# RT register map
Vendor: Texas Instruments
Peripheral module from a debugger description file (folder omap36xx).
Registers are 64-bit, read-only, reset values left out (the file's numbers can be read two ways) unless marked. A register's access mark holds for its fields unless they carry their own. Offsets are as the file gives them; lines under a group give offsets from that group; [hi:lo] are bit positions; {n}, {i} and the like mark numbered series; 'fields as' and 'values as' point back to an identical list; <NAME> marks a mode.

## RT
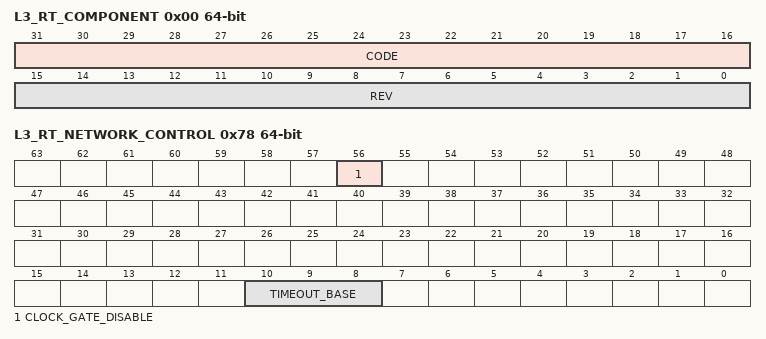
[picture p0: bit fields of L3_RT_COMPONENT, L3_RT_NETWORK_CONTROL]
0x00 L3_RT_COMPONENT — This register identifies the component to which this register block belongs.
  [31:16] CODE — Component Code
  [15:0] REV — Revision of the component
0x10 L3_RT_NETWORK — This register identifies the interconnect and is present only in the register target.
  [63:32] ID — Unique Interconnect ID
0x70 L3_RT_INITID_READBACK — This register is used by initiators to discover their own identity.
  [7:0] INITID — Returns initiator ID of core thread that initiated the read
0x78 L3_RT_NETWORK_CONTROL access per field — It controls such interconnect wide functions as the timeout base scale and the disabling of fine grained hardware clock gating.
  [56] CLOCK_GATE_DISABLE rw — Overrides fine grained hardware clock gating
  [10:8] TIMEOUT_BASE rw — Timeout base period in register target clock cyclesProgram the timeout base period. Each of the agent timeout features is programmed as a multiple of the timeout base period. These timeout bases are: .
    0=Timeout disabled; 1=L3 interconnect clock cycles divided by 64; 2=L3 interconnect clock cycles divided by 256; 3=L3 interconnect clock cycles divided by 1024; 4=L3 interconnect clock cycles divided by 4096
